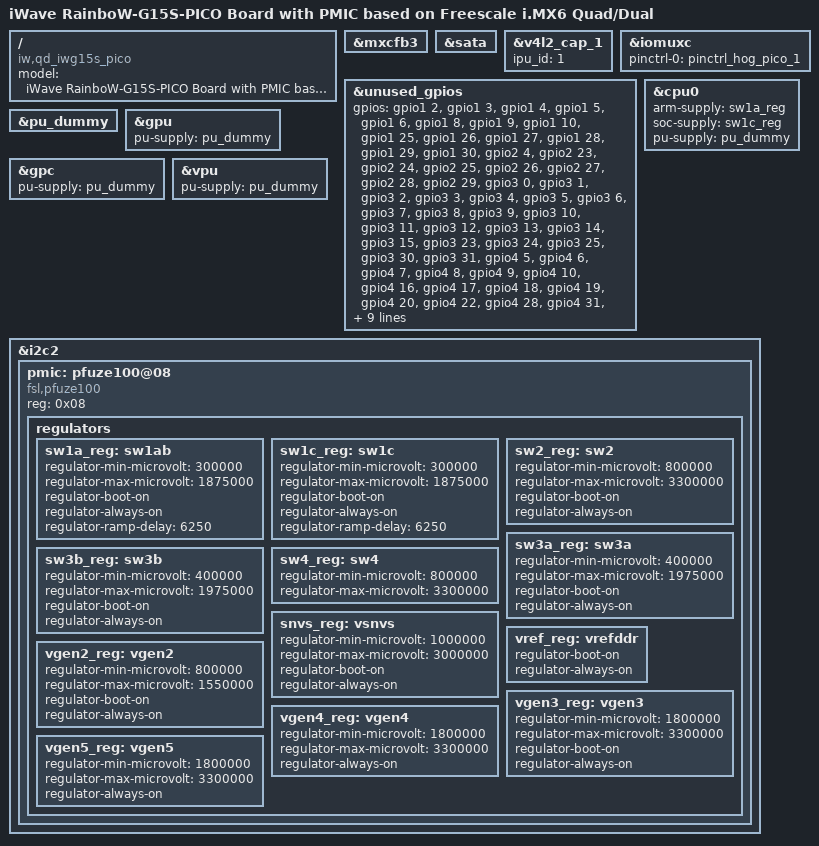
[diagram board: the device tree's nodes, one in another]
/*
 * Copyright (c) 2015 iWave Systems Technologies Pvt. Ltd.
 *
 * The code contained herein is licensed under the GNU General Public
 * License. You may obtain a copy of the GNU General Public License
 * Version 2 or later at the following locations:
 *
 * http://www.opensource.org/licenses/gpl-license.html
 * http://www.gnu.org/copyleft/gpl.html
 */

/dts-v1/;

#include "imx6q_iwg15.dtsi"
#include "imx6qdl-iwg15s-pico.dtsi"

/ {
	model = "iWave RainboW-G15S-PICO Board with PMIC based on Freescale i.MX6 Quad/Dual";
	compatible = "iw,qd_iwg15s_pico", "fsl,imx6q";
};

&mxcfb3 {
	status = "okay";
};

&sata {
	status = "okay";
};

&v4l2_cap_1 {
        ipu_id = <1>;
};

&iomuxc {
        pinctrl-names = "default";
        pinctrl-0 = <&pinctrl_hog_pico_1>;
};

&unused_gpios {
	gpios = <&gpio1 2 0  &gpio1 3 0   &gpio1 4 0   &gpio1 5 0
		&gpio1 6 0   &gpio1 8 0   &gpio1 9 0   &gpio1 10 0
		&gpio1 25 0  &gpio1 26 0  &gpio1 27 0  &gpio1 28 0
		&gpio1 29 0  &gpio1 30 0  &gpio2 4 0   &gpio2 23 0
		&gpio2 24 0  &gpio2 25 0  &gpio2 26 0  &gpio2 27 0
		&gpio2 28 0  &gpio2 29 0  &gpio3 0 0   &gpio3 1 0
		&gpio3 2 0   &gpio3 3 0   &gpio3 4 0   &gpio3 5 0
		&gpio3 6 0   &gpio3 7 0   &gpio3 8 0   &gpio3 9 0
		&gpio3 10 0  &gpio3 11 0  &gpio3 12 0  &gpio3 13 0
		&gpio3 14 0  &gpio3 15 0  &gpio3 23 0
		&gpio3 24 0  &gpio3 25 0  &gpio3 30 0  &gpio3 31 0
		&gpio4 5 0   &gpio4 6 0   &gpio4 7 0   &gpio4 8 0
		&gpio4 9 0   &gpio4 10 0  &gpio4 16 0  &gpio4 17 0
		&gpio4 18 0  &gpio4 19 0  &gpio4 20 0  &gpio4 22 0
		//&gpio4 28 0  &gpio4 29 0  &gpio4 30 0  &gpio4 31 0
		&gpio4 28 0  &gpio4 31 0
		&gpio5 0  0  &gpio5 8 0   &gpio5 9 0   &gpio5 10 0
		&gpio5 11 0  &gpio5 16 0  &gpio5 17 0  &gpio5 18 0
		&gpio5 19 0  &gpio5 20 0  &gpio5 21 0  &gpio5 22 0
		&gpio5 23 0  &gpio5 24 0  &gpio5 25 0  &gpio5 26 0
		&gpio5 27 0  &gpio5 28 0  &gpio5 29 0  &gpio5 30 0
		&gpio5 31 0  &gpio6 0 0   &gpio6 1 0   &gpio6 2 0
		&gpio6 3 0   &gpio6 4 0   &gpio6 5 0   &gpio6 7 0
		&gpio6 9 0   &gpio6 10 0  &gpio6 14 0  &gpio6 15 0
		&gpio6 16 0  &gpio6 31 0  &gpio7 8 0   &gpio7 11 0  
		&gpio7 12 0>;
};

&cpu0 {
        arm-supply = <&sw1a_reg>;
        soc-supply = <&sw1c_reg>;
        pu-supply = <&pu_dummy>; /* use pu_dummy if VDDSOC share with VDDPU */
};

&pu_dummy {
	status = "okay";
};

&gpu {
        pu-supply = <&pu_dummy>; /* ldo-bypass:use pu_dummy if VDDSOC share with VDDPU */
};

&gpc {
        pu-supply = <&pu_dummy>; /* ldo-bypass:use pu_dummy if VDDSOC share with VDDPU */
};

&vpu {
        pu-supply = <&pu_dummy>; /* ldo-bypass:use pu_dummy if VDDSOC share with VDDPU */
};

&i2c2 {
	pmic: pfuze100@08 {
		compatible = "fsl,pfuze100";
		reg = <0x08>;

		regulators {
			sw1a_reg: sw1ab {
				regulator-min-microvolt = <300000>;
				regulator-max-microvolt = <1875000>;
				regulator-boot-on;
				regulator-always-on;
				regulator-ramp-delay = <6250>;
			};

			sw1c_reg: sw1c {
				regulator-min-microvolt = <300000>;
				regulator-max-microvolt = <1875000>;
				regulator-boot-on;
				regulator-always-on;
				regulator-ramp-delay = <6250>;
			};

			sw2_reg: sw2 {
				regulator-min-microvolt = <800000>;
				regulator-max-microvolt = <3300000>;
				regulator-boot-on;
				regulator-always-on;
			};

			sw3a_reg: sw3a {
				regulator-min-microvolt = <400000>;
				regulator-max-microvolt = <1975000>;
				regulator-boot-on;
				regulator-always-on;
			};

			sw3b_reg: sw3b {
				regulator-min-microvolt = <400000>;
				regulator-max-microvolt = <1975000>;
				regulator-boot-on;
				regulator-always-on;
			};

			sw4_reg: sw4 {
				regulator-min-microvolt = <800000>;
				regulator-max-microvolt = <3300000>;
			};

			snvs_reg: vsnvs {
				regulator-min-microvolt = <1000000>;
				regulator-max-microvolt = <3000000>;
				regulator-boot-on;
				regulator-always-on;
			};

			vref_reg: vrefddr {
				regulator-boot-on;
				regulator-always-on;
			};

			vgen2_reg: vgen2 {
				regulator-min-microvolt = <800000>;
				regulator-max-microvolt = <1550000>;
				regulator-boot-on;
				regulator-always-on;
			};

			vgen3_reg: vgen3 {
				regulator-min-microvolt = <1800000>;
				regulator-max-microvolt = <3300000>;
				regulator-boot-on;
				regulator-always-on;
			};

			vgen4_reg: vgen4 {
				regulator-min-microvolt = <1800000>;
				regulator-max-microvolt = <3300000>;
				regulator-always-on;
			};

			vgen5_reg: vgen5 {
				regulator-min-microvolt = <1800000>;
				regulator-max-microvolt = <3300000>;
				regulator-always-on;
			};

		};
	};
};
